# hercules_usb_ohci_tms570ls3x register map
Vendor: Texas Instruments
Peripheral module from a debugger description file (folder hercules).
Registers are 32-bit, access per field, reset 0x0 unless marked. A register's access mark holds for its fields unless they carry their own. Offsets are as the file gives them; lines under a group give offsets from that group; [hi:lo] are bit positions; {n}, {i} and the like mark numbered series; 'fields as' and 'values as' point back to an identical list; <NAME> marks a mode.

## OHCI
0x00 HCREVISION ro reset 0x10 — OHCI revision number
  [7:0] REV — OHCI specification revision the OHCI revision number upon which the USB host controller is based.Examples: 0x10 for 1.0 0x21 for 2.1
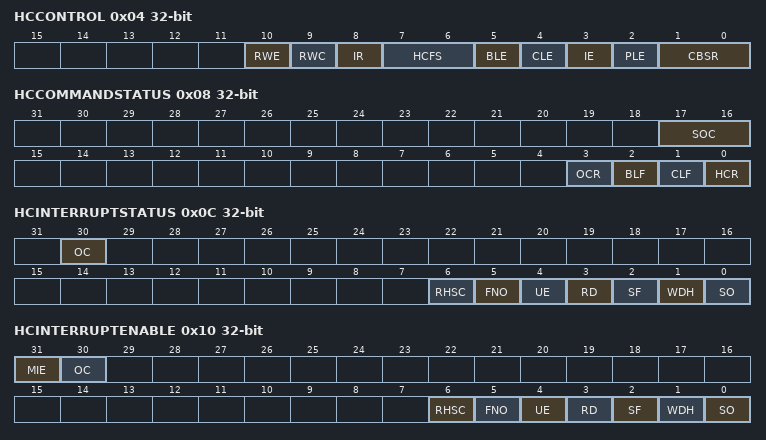
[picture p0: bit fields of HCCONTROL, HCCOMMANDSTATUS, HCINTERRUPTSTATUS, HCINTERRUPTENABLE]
0x04 HCCONTROL — HC Operating Mode Register
  [10] RWE rw — Remote wake-up enableThis bit is used to enable or disable the remote wakeup feature upon detection of upstream resume signaling. .
  [9] RWC rw — Remote wake-up connected.This bit indicates whether the host controller supports remote wakeup signaling. .
  [8] IR rw — Interrupt routing.This bit determines the routing of interrupts generated by events registered in USBHOST.. .
    0=All interrupts are routed to the normal host bus interrupt mechanism; 1=interrupts are routed to the system management Interrupt
  [7:6] HCFS rw — Host Controller Functional State
    0=HCFS: USB Reset; 1=HCFS: USB Resume; 2=HCFS: USB Operational; 3=HCFS: USB Suspend
  [5] BLE rw — Bulk list processing enable.
    0=Bulk ED list is not processed after the next SOF; 1=Enables processing of bulk ED list in the next frame
  [4] CLE rw — Control list processing enable.
    0=Control ED list is not processed after the next SOF; 1=Enables processing of control ED list in the next frame
  [3] IE rw — Isochronous ED processing enabled by Host Controller Driver.
    0=Isochronous EDs are not processed; 1=Enables processing of isochronous EDs
  [2] PLE rw — Periodic list enable
    0=Periodic ED lists are not processed after the next frame; 1=Enables processing of periodic ED lists in the next frame
  [1:0] CBSR rw — Control/bulk service ratio. Specifies the ratio between control and bulk EDs processed in a frame.
    0=One control ED per bulk ED; 1=Two control ED per bulk ED; 2=Three control ED per bulk ED; 3=Four control ED per bulk ED
0x08 HCCOMMANDSTATUS — HC Command and Status
  [17:16] SOC ro — Scheduling overrun count.This is used to monitor any persistent scheduling problems. . These bits are incremented on each scheduling overrun error. It is initialized to 0x0 and wraps around at 0x3. .
  [3] OCR rw — Ownership change request.This bit is set to request a change of control of the host controller. .
  [2] BLF rw — Bulk list filled.This bit is used to indicate whether there are any TDs on the bulk list. It is set whenever it adds a TD to an ED in the bulk list. .
  [1] CLF rw — Control list filled.This bit is used to indicate whether there are any TDs on the control list. It is set whenever it adds a TD to an ED in the control list. .
  [0] HCR rw — Host controller reset. (software reset) Set this bit to initiate a USB host controller reset. This resets most USB host controller OHCI registers. OHCI register accesses must not be attempted until a read of this register returns a 0.
    0=No effect; 1=USB host controller is reset
0x0C HCINTERRUPTSTATUS
  [30] OC ro — Ownership change.This bit is set when the USBHOST.[3] OCR bit is set. .
    1=OC_1_r (An ownership change has occurred.); 0=OC_0_w (No effect); 1=OC_1_w (Clears this bit)
  [6] RHSC rw — Root hub status change.When 0x1: A root hub status change has occurred.Write 0x0: No effect.Write 0x1: Clears this bit.
  [5] FNO rw — Frame number overflow.When 0x1: A frame number overflow has occurred.Write 0x0: No effect.Write 0x1: Clears this bit.
  [4] UE rw — Unrecoverable error.When 0x1: An unrecoverable error has occurred.Write 0x0: No effect.Write 0x1: Clears this bit.
  [3] RD rw — Resume detected.When 0x1: A downstream device has issued a resume request.Write 0x0: No effect.Write 0x1: Clears this bit.
  [2] SF rw — Start of frame.When 0x1: A SOF has been issued.Write 0x0: No effect.Write 0x1: Clears this bit.
  [1] WDH rw — Write done head.When 0x1: The USB host controller has updated the HCDONEHEAD register.Write 0x0: No effect.Write 0x1: Clears this bit.
  [0] SO rw — Scheduling overrun.When 0x1: A scheduling overrun has occurred.Write 0x0: No effect.Write 0x1: Clears this bit
0x10 HCINTERRUPTENABLE
  [31] MIE rw — Master interrupt enable.When 0x1: Allows other enabled OHCI interrupt sources to propagate to the device interrupt controller.When 0x0: OHCI interrupt sources are ignored.Write 0x0: No effect.Write 0x1: Sets this bit.
  [30] OC rw — Ownership change.
    0=OC_0_w (No effect.); 1=OC_1_w (Enable interrupt generation due to ownership change.)
  [6] RHSC rw — Root hub status change.When 0x1 and MIE is 0x1: Allows root hub status change interrupts to propagate to the device interrupt controller.When 0x0 or MIE is 0x0: Root hub status change interrupts do not propagate.Write 0x0: No effect.Write 0x1: Sets this bit.
  [5] FNO rw — Frame number overflow.When 0x1 and MIE is 0x1: Allows FNO interrupts to propagate to the device interrupt controller.When 0x0 or MIE is 0x0: FNO interrupts do not propagate.Write 0x0: No effect.Write 0x1: Sets this bit.
  [4] UE rw — Unrecoverable error.When 0x1 and MIE is 0x1: Allows UE interrupts to propagate to the device interrupt controller.When 0x0 or MIE is 0x0: UE interrupts do not propagate.Write 0x0: No effect.Write 0x1: Sets this bit.
  [3] RD rw — Resume detected.When 0x1 and MIE is 0x1: Allows RD interrupts to propagate to the device interrupt controller.When 0x0 or MIE is 0x0: RD interrupts do not propagate.Write 0x0: No effect.Write 0x1: Sets this bit.
  [2] SF rw — Start of frame.When 0x1 and MIE is 0x1: Allows SF interrupts to propagate to the device interrupt controller.When 0x0 or MIE is 0x0: SF interrupts do not propagate.Write 0x0: No effect.Write 0x1: Sets this bit.
  [1] WDH rw — Write done head.When 0x1 and MIE is 0x1: Allows WDH interrupts to propagate to the device interrupt controller.When 0x0 or MIE is 0x0: WDH interrupts do not propagate.Write 0x0: No effect.Write 0x1: Sets this bit.
  [0] SO rw — Scheduling overrun.When 0x1 and MIE is 0x1: Allows SO interrupts to propagate to the device interrupt controller.When 0x0 or MIE is 0x0: SO interrupts do not propagate.Write 0x0: No effect.Write 0x1: Sets this bit.
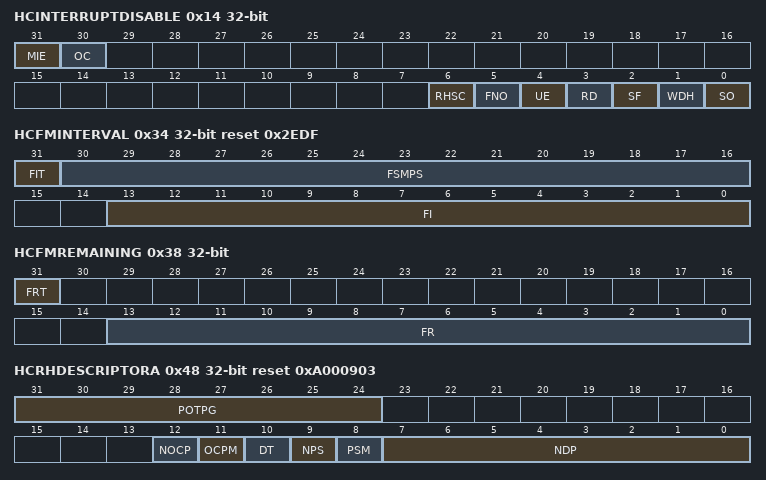
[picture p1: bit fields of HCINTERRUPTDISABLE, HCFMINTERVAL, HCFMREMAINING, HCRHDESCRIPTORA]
0x14 HCINTERRUPTDISABLE
  [31] MIE rw — Master interrupt enable.Always reads 0x0.Write 0x0: No effect.Write 0x1: Clears the HCINTERRUPTENABLE MIE bit.
  [30] OC rw — Ownership change.
    0=OC_0_w (No effect.); 1=OC_1_w (Disable interrupt generation due to ownership change.)
  [6] RHSC rw — Root hub status change.Always reads 0x0.Write 0x0: No effect.Write 0x1: Clears the HCINTERRUPTENABLE RHSC bit.
  [5] FNO rw — Frame number overflow.Always reads 0x0.Write 0x0: No effect.Write 0x1: Clears the HCINTERRUPTENABLE FNO bit.
  [4] UE rw — Unrecoverable error.Always reads 0x0.Write 0x0: No effect.Write 0x1: Clears the HCINTERRUPTENABLE UE bit.
  [3] RD rw — Resume detected.Always reads 0x0.Write 0x0: No effect.Write 0x1: Clears the HCINTERRUPTENABLE RD bit.
  [2] SF rw — Start of frame.Always reads 0x0.Write 0x0: No effect.Write 0x1: Clears the HCINTERRUPTENABLE SF bit.
  [1] WDH rw — Write done head.Always reads 0x0.Write 0x0: No effect.Write 0x1: Clears the HCINTERRUPTENABLE WDH bit.
  [0] SO rw — Scheduling overrun.Always reads 0x0.Write 0x0: No effect.Write 0x1: Clears the HCINTERRUPTENABLE SO bit.
0x18 HCHCCA — HC HCCA Address Register
  [31:8] HCCA rw — Physical address of the beginning of the HCCA.
0x1C HCPERIODCURRENTED ro — HC Current Periodic Register
  [31:4] PCED — Physical address of current ED on the periodic ED list.
0x20 HCCONTROLHEADED — HC Head Control Register
  [31:4] CHED rw — Physical address of head ED on the control ED list.
0x24 HCCONTROLCURRENTED — HC Current Control Register
  [31:4] CCED rw — Physical address of current ED on the control ED list.
0x28 HCBULKHEADED — HC Head Bulk Register
  [31:4] BHED rw — Physical address of head ED on the bulk ED list.
0x2C HCBULKCURRENTED — HC Current Bulk Register
  [31:4] BCED rw — Physical address of current ED on the bulk ED list.
0x30 HCDONEHEAD ro — HC Head Done Register
  [31:4] DH — Physical address of last TD that was added to the Done queue.
0x34 HCFMINTERVAL reset 0x2EDF — HC Frame Interval Register
  [31] FIT rw — Frame interval toggle.This bit is toggled whenever it loads a new value to FI. .
  [30:16] FSMPS rw — Largest data packet size for full-speed packets, bit times.This field specifies a value which is loaded into the largest data packet counter at the beginning of each frame. .
  [13:0] FI rw — Frame interval. Number of 12-MHz clocks in the USB frame. The nominal value is set to 11,999, to give a 1-ms frame.
0x38 HCFMREMAINING ro — HC Frame Remaining Register
  [31] FRT — Frame remaining toggle.This bit is used for the synchronization between USBHOST.[13:0] FI and FR. . This bit is loaded from the USBHOST.[31] FIT field whenever FR reaches 0. .
  [13:0] FR — Frame remaining.This counter is decremented at each bit time. When it reaches 0, it is reset by loading the USBHOST.[13:0] FI value at the next bit time boundary. .
0x3C HCFMNUMBER ro — HC Frame Number Register
  [15:0] FN — Frame Number.This is incremented when USBHOST. is reloaded. It is rolled over to 0x0000 after 0xFFFF. .
0x40 HCPERIODICSTART
  [13:0] PS rw — Periodic start. The host controller driver must program this value to be about 10% less than the frame interval field value so that control and bulk EDs have priority for the first 10% of the frame; then periodic EDs have priority for the remaining 90% of the frame.
0x44 HCLSTHRESHOLD reset 0x628 — HC Low-Speed Threshold Register
  [11:0] LST rw — Low-speed threshold.
0x48 HCRHDESCRIPTORA reset 0xA000903 — HC Root Hub A Register
  [31:24] POTPG rw — Power-on to power-good time. Defines the minimum amount of time (2 ms * POTPG) between the USB host controller turning on power to a downstream port and when the USB host can access the downstream device.
  [12] NOCP rw — No overcurrent protection. 0x0: Overcurrent status is reported collectively for all downstream ports.0x1: The USB host controller does not implement overcurrent protection inputs The bit must not be used, and is always written to with its default (reset) value as the hardware overcurrent inputs are tied off at device level.
  [11] OCPM rw — Overcurrent protection mode. The bit must not be used, and is always written to with its default (reset) value as the hardware overcurrent inputs are tied off at device level.
  [10] DT ro — Device type.Always reads 0x0: Indicates that the USB host controller implemented is not a compound device.
  [9] NPS rw — No power switching
    0=VBUS power switching is supported, either per-port or all-port switched per the power; 1=VBUS power switching is not supported, power is available to all downstream ports
  [8] PSM rw — Power switching mode.
    0=Indicates that all ports are powered at the same time; 1=Individual port power switching is supported
  [7:0] NDP ro — Number of downstream ports.These bits specify the number of downstream ports supported by the root hub. It is implementation-specific. The minimum number of ports is 1. The maximum number of ports supported by OHCI is 15.
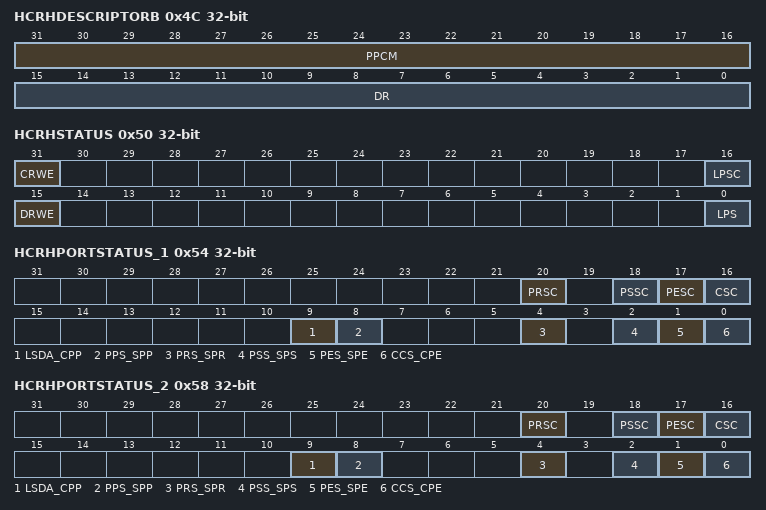
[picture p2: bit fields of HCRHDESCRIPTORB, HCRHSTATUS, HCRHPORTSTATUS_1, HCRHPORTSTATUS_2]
0x4C HCRHDESCRIPTORB rw — HC Root Hub B Register
  [31:16] PPCM — Port power control mask. Each bit defines whether a corresponding downstream port has port power controlled by the global power control. When set the port's power state is only affected by per-port power control. When cleared the port is controlled by the global power switch. If the device is configured to global switch mode this field is not valid. bit 0: Reserved, bit 1: Ganged-power mask on port 1, ..., bit 15: Ganged-power mask on port 15
  [15:0] DR — Device removable. Each bit defines whether a corresponding downstream port has a removable device. When cleared the attached device is removable. When set the attached device is not removable. Bit 0: Reserved, bit 1 : Device attached to port 1, , bit 15: Device attached to port 15
0x50 HCRHSTATUS — HC Root Hub Status Register
  [31] CRWE wo — Clear remote wake-up enable.Write 0x0: No effect.Write 0x1: Clears the device remote wake-up enable bit.
  [16] LPSC rw — Local power status change.Always reads 0x0: The Root Hub does not support the local power status featureWrite 0x0: No effect.Write 0x1: Sets port power status bits for all ports, if power switching mode is 0. Sets port power status bits for ports with their corresponding port power control mask bits cleared if power switching mode is 1.
  [15] DRWE rw — Device remote wake-up enable. Enables a connect status change event as a resume event, causing a USB suspend to USB resume state transition and sets the resume detected interrupt status bit.Read 0x1: Connect status change is a remote wake-up event.Read 0x0: Connect status change is not a remote wake-up event.Write 0x0: No effect.Write 0x1: Sets the device remote wake-up enable bit.
  [0] LPS rw — Local power status.Always reads 0x0.Write 0x0: No effect.Write 0x1: When in global power mode (power switching mode = 0), turns off power to all ports. If in per-port power mode (power switching mode = 1), turns of power to those ports whose corresponding port power control mask bit is 0.
0x54 HCRHPORTSTATUS_1 — HC Port 1 Status and Control Register
  [20] PRSC rw — Port 1 reset status change. This bit is set when the Port 1 port reset status bit has changed.Write 0x0: No effect.Write 0x1: Clears this bit.
  [18] PSSC rw — Port 1 suspend status change. This bit is set when the Port1 port suspend status has changed.Write 0x0: No effect.Write 0x1: Clears this bit.
  [17] PESC rw — Port 1 enable status change. This bit is set when the Port1 port enable status has changed.Write 0x0: No effect.Write 0x1: Clears this bit.
  [16] CSC rw — Port 1 connect status change. This bit is set when the Port1 port current connect status has changed due to a connect or disconnect event. If current connect status is 0 when a set port reset, set port enable, or set port suspend write occurs, this bit is set.Write 0x0: No effect.Write 0x1: Clears this bit.Note: If the DR bit HCRHDESCRIPTORB[1] is set, this bit is set only after a root hub reset to inform the system that the device is attached.
  [9] LSDA_CPP rw — Port 1 low-speed device attached/clear port power. This bit is valid only when port 1 current connect status is 1.Read 0x0: A full-speed device is attached to port 1.Read 0x1: A low-speed device is attached to port 1.Write 0x0: No effect.Write 0x1: Clears the port 1 port power status.
  [8] PPS_SPP rw — Port 1 port power status/set port power.Read 0x0: Port 1 power is enabled.Read 0x1: Port 1 power is not enabled.Write 0x0: No effect.Write 0x1: Sets the port 1 port power status bit.
  [4] PRS_SPR rw — Port 1 port reset status/set port reset.Read 0x0: USB reset is not being sent to port 1.Read 0x1: Port 1 is signaling the USB reset.Write 0x0: No effect.Write 0x1: Sets the port 1 port reset status bit and causes the USB host controller to begin signaling USB reset to port 1.
  [2] PSS_SPS rw — Port 1 port suspend status/set port suspend. This bit is cleared automatically at the end of the USB resume sequence and also at the end of the USB reset sequence.Write 0x0: No effect.Read 0x0: Port 1 is not in the USB suspend state.Read 0x1: Port 1 is in the USB suspend state or is in the resume sequence.Write 0x1: If port 1 current connect status is 1, sets the port 1 port suspend status bit and places port 1 in USB suspend state. If current connect status is 0, sets instead connect status change to inform the USB host controller driver of an attempt to suspend a disconnected port.
  [1] PES_SPE rw — Port 1 port enable status/set port enable. This bit is automatically set at completion of port 1 USB reset if it was not already set before the USB reset completed, and is automatically set at the end of a USB suspend if the port was not enabled when the USB resume completed.Read 0x0: Port 1 is not enabled.Read 0x1: Port 1 is enabled.Write 0x0: No effect.Write 0x1: When port 1 current connect status is 1 sets the port 1 port enable status bit. When port 1 current status is 0 has no effect.
  [0] CCS_CPE rw — Port 1 current connection status/clear port enable.Read 0x0: No USB device is attached to port 1.Read 0x1: Port 1 currently has a USB device attached.Write 0x0: No effect.Write 0x1: Clears the port 1 port enable bit.Note: This bit is set to 1 if the DR bit HCRHDESCRIPTORB[1] is set to indicate a non-removable device on port 1.
0x58 HCRHPORTSTATUS_2 — HC Port 2 Status and Control Register
  [20] PRSC rw — Port 2 reset status change. This bit is set when the Port 2 port reset status bit has changed.Write 0x0: No effect.Write 0x1: Clears this bit.
  [18] PSSC rw — Port 2 suspend status changed. This bit is set when the Port 2 port suspend status has changed.Write 0x0: No effect.Write 0x1: Clears this bit.
  [17] PESC rw — Port 2 enable status change. This bit is set when the Port 2 port enable status has changed.Write 0x0: No effect.Write 0x1: Clears this bit.
  [16] CSC rw — Port 2 connect status change. This bit is set when the Port 2 port current connect status has changed due to a connect or disconnect event.If current connect status is 0 when a set port reset, set port enable, or set port suspend write occurs, this bit is set.Write 0x0: No effect.Write 0x1: Clears this bit.Note: If the DR bit HCRHDESCRIPTORB[1] is set, this bit is set only after a root hub reset to inform the system that the device is attached.
  [9] LSDA_CPP rw — Port 2 low-speed device attached/clear port power. This bit is valid only when port 2 current connect status is 1.Read 0x0: A full-speed device is attached to port 2.Read 0x1: A low-speed device is attached to port 2.Write 0x0: No effect.Write 0x1: Clears the port 2 port power status.
  [8] PPS_SPP rw — Port 2 port power status/set port power.Read 0x0: Port 2 power is enabled.Read 0x1: Port 2 power is not enabled.Write 0x0: No effect.Write 0x1: Sets the port 2 port power status bit.
  [4] PRS_SPR rw — Port 2 port reset status/set port reset.Read 0x0: USB reset is not being sent to port 2.Read 0x1: Port 2 is signaling the USB reset.Write 0x0: No effect.Write 0x1: Sets the port 2 port reset status bit and causes the USB host controller to begin signaling USB reset to port 2.
  [2] PSS_SPS rw — Port 2 port suspend status/set port suspend. This bit is cleared automatically at the end of the USB resume sequence and also at the end of the USB reset sequence.Write 0x0: No effect.Read 0x0: Port 2 is not in the USB suspend state.Read 0x1: Port 2 is in the USB suspend state or is in the resume sequence.Write 0x1: If port 2 current connect status is 1, sets the port 2 port suspend status bit and places port 2 in USB suspend state. If current connect status is 0, sets instead connect status change to inform the USB host controller driver of an attempt to suspend a disconnected port.
  [1] PES_SPE rw — Port 2 port enable status/set port enable. This bit is automatically set at completion of port 2 USB reset if it was not already set before the USB reset completed, and is automatically set at the end of a USB suspend if the port was not enabled when the USB resume completed.Read 0x0: Port 2 is not enabled.Read 0x1: Port 2 is enabled.Write 0x0: No effect.Write 0x1: When port 2 current connect status is 1 sets the port 2 port enable status bit. When port 2 current status is 0 has no effect.
  [0] CCS_CPE rw — Port 2 current connection status/clear port enable.Read 0x0: No USB device is attached to port 2.Read 0x1: Port 2 currently has a USB device attached.Write 0x0: No effect.Write 0x1: Clears the port 2 port enable bit.Note: This bit is set to 1 if the DR bit HCRHDESCRIPTORB[1] is set to indicate a non-removable device on port 2.
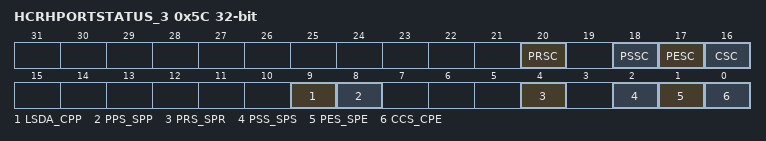
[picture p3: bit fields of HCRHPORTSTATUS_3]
0x5C HCRHPORTSTATUS_3 — HC Port 3 Status and Control Register
  [20] PRSC rw — Port 3 reset status change. This bit is set when the Port 3 port reset status bit has changed.Write 0x0: No effect.Write 0x1: Clears this bit.
  [18] PSSC rw — Port 3 suspend status change. This bit is set when the Port 3 port suspend status has changed.Write 0x0: No effect.Write 0x1: Clears this bit.
  [17] PESC rw — Port 3 enable status change. This bit is set when the Port 3 port enable status has changed.Write 0x0: No effect.Write 0x1: Clears this bit.
  [16] CSC rw — Port 3 connect status change. This bit is set when the Port 3 port current connect status has changed due to a connect or disconnect event.If current connect status is 0 when a set port reset, set port enable, or set port suspend write occurs, this bit is set.Write 0x0: No effect.Write 0x1: Clears this bit.Note: If the DR bit HCRHDESCRIPTORB[1] is set, this bit is set only after a root hub reset to inform the system that the device is attached.
  [9] LSDA_CPP rw — Port 3 low-speed device attached/clear port power. This bit is valid only when port 3 current connect status is 1.Read 0x0: A full-speed device is attached to port 3.Read 0x1: A low-speed device is attached to port 3.Write 0x0: No effect.Write 0x1: Clears the port 3 port power status.
  [8] PPS_SPP rw — Port 3 power status/set port power.Read 0x0: Port 3 power is enabled.Read 0x1: Port 3 power is not enabled.Write 0x0: No effect.Write 0x1: Sets the port 3 port power status bit.
  [4] PRS_SPR rw — Port 3 reset status/set port reset.Read 0x0: USB reset is not being sent to port 3.Read 0x1: Port 3 is signaling the USB reset.Write 0x0: No effect.Write 0x1: Sets the port 3 port reset status bit and causes the USB host controller to begin signaling USB reset to port 3.
  [2] PSS_SPS rw — Port 3 port suspend status/set port suspend. This bit is cleared automatically at the end of the USB resume sequence and also at the end of the USB reset sequence.Write 0x0: No effect.Read 0x0: Port 3 is not in the USB suspend state.Read 0x1: Port 3 is in the USB suspend state or is in the resume sequence.Write 0x1: If port 3 current connect status is 1, sets the port 3 port suspend status bit and places port 3 in USB suspend state. If current connect status is 0, sets instead connect status change to inform the USB host controller driver of an attempt to suspend a disconnected port.
  [1] PES_SPE rw — Port 3 enable status/set port enable. This bit is automatically set at completion of port 3 USB reset if it was not already set before the USB reset completed, and is automatically set at the end of a USB suspend if the port was not enabled when the USB resume completed.Read 0x0: Port 3 is not enabled.Read 0x1: Port 3 is enabled.Write 0x0: No effect.Write 0x1: When port 3 current connect status is 1 sets the port 3 port enable status bit. When port 3 current status is 0 has no effect.
  [0] CCS_CPE rw — Port 3 current connection status/clear port enable.Read 0x0: No USB device is attached to port 3.Read 0x1: Port 3 currently has a USB device attached.Write 0x0: No effect.Write 0x1: Clears the port 3 port enable bit.Note: This bit is set to 1 if the DR bit HCRHDESCRIPTORB[1] is set to indicate a non-removable device on port 3.
0xE0 HOSTUEADDR access not given reset not defined
0xE4 HOSTUESTATUS access not given reset not defined
0xE8 HOSTTIMEOUTCTRL access not given reset not defined
0xEC HOSTREVISION access not given reset not defined
